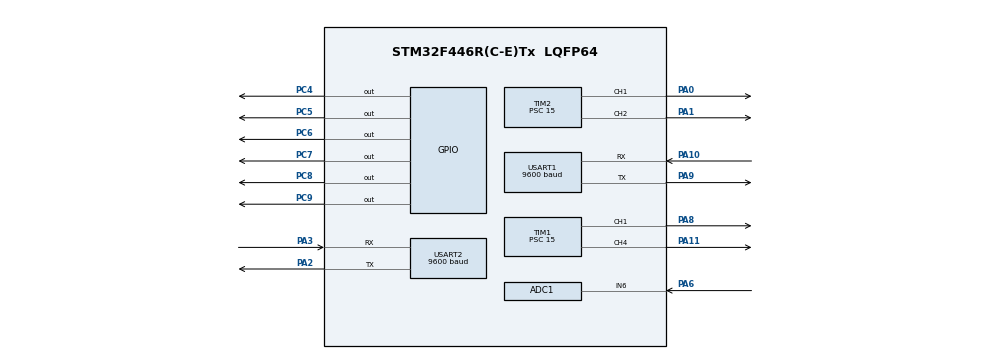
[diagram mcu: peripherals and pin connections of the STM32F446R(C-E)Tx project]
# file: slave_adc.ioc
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ADC1.Channel-0\#ChannelRegularConversion=ADC_CHANNEL_6
ADC1.NbrOfConversionFlag=1
ADC1.Rank-0\#ChannelRegularConversion=1
ADC1.Resolution=ADC_RESOLUTION_12B
ADC1.SamplingTime-0\#ChannelRegularConversion=ADC_SAMPLETIME_3CYCLES
ADC1.master=1
Mcu.Family=STM32F4
Mcu.Name=STM32F446R(C-E)Tx
Mcu.Package=LQFP64
NVIC.PriorityGroup=NVIC_PRIORITYGROUP_4
NVIC.USART1_IRQn=true\:0\:0\:false\:false\:true\:true\:true\:true
NVIC.USART2_IRQn=true\:0\:0\:false\:false\:true\:true\:true\:true
PA0-WKUP.Signal=S_TIM2_CH1_ETR
PA1.Signal=S_TIM2_CH2
PA10.Mode=Asynchronous
PA10.Signal=USART1_RX
PA11.Signal=S_TIM1_CH4
PA13.Mode=Serial_Wire
PA13.Signal=SYS_JTMS-SWDIO
PA14.Mode=Serial_Wire
PA14.Signal=SYS_JTCK-SWCLK
PA2.Mode=Asynchronous
PA2.Signal=USART2_TX
PA3.Mode=Asynchronous
PA3.Signal=USART2_RX
PA6.Signal=ADCx_IN6
PA8.Signal=S_TIM1_CH1
PA9.Mode=Asynchronous
PA9.Signal=USART1_TX
PC4.Signal=GPIO_Output
PC5.Signal=GPIO_Output
PC6.Signal=GPIO_Output
PC7.Signal=GPIO_Output
PC8.Signal=GPIO_Output
PC9.Signal=GPIO_Output
ProjectManager.HeapSize=0x200
ProjectManager.StackSize=0x400
ProjectManager.TargetToolchain=STM32CubeIDE
RCC.CortexFreq_Value=16000000
RCC.USBFreq_Value=96000000
RCC.VCOOutputFreq_Value=192000000
SH.ADCx_IN6.0=ADC1_IN6,IN6
SH.S_TIM1_CH1.0=TIM1_CH1,PWM Generation1 CH1
SH.S_TIM1_CH4.0=TIM1_CH4,PWM Generation4 CH4
SH.S_TIM2_CH1_ETR.0=TIM2_CH1,PWM Generation1 CH1
SH.S_TIM2_CH2.0=TIM2_CH2,PWM Generation2 CH2
TIM1.Channel-PWM\ Generation1\ CH1=TIM_CHANNEL_1
TIM1.Channel-PWM\ Generation4\ CH4=TIM_CHANNEL_4
TIM1.Period=19999
TIM1.Prescaler=15
TIM2.Channel-PWM\ Generation1\ CH1=TIM_CHANNEL_1
TIM2.Channel-PWM\ Generation2\ CH2=TIM_CHANNEL_2
TIM2.Period=999
TIM2.Prescaler=15
USART1.BaudRate=9600
USART1.VirtualMode=VM_ASYNC
USART2.BaudRate=9600
USART2.VirtualMode=VM_ASYNC
board=custom

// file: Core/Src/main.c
/* USER CODE BEGIN Header */
/**
  ******************************************************************************
  * @file           : main.c
  * @brief          : Main program body
  ******************************************************************************
  * @attention
  *
  * Copyright (c) 2023 STMicroelectronics.
  * All rights reserved.
  *
  * This software is licensed under terms that can be found in the LICENSE file
  * in the root directory of this software component.
  * If no LICENSE file comes with this software, it is provided AS-IS.
  *
  ******************************************************************************
  */
/* USER CODE END Header */
#include "main.h"
#include "adc.h"
#include "tim.h"
#include "usart.h"
#include "gpio.h"

/* USER CODE BEGIN PD */
#define BUFFER_LEN 2
/* USER CODE END PD */

/* USER CODE BEGIN PV */
uint8_t RX_BUFFER[BUFFER_LEN] = {125, 125};
uint8_t i = 0;
uint8_t n = BUFFER_LEN;
uint8_t temp = 0;
uint32_t voltage;
/* USER CODE END PV */

void SystemClock_Config(void);
/* USER CODE BEGIN PFP */
void HAL_UART_RxCpltCallback(UART_HandleTypeDef *huart)
{
	if(huart->Instance == huart1.Instance)
	{

      HAL_UART_Receive_IT(&huart1, RX_BUFFER, sizeof (RX_BUFFER));

	}
}
/* USER CODE END PFP */

int main(void)
{

  /* MCU Configuration--------------------------------------------------------*/

  /* Reset of all peripherals, Initializes the Flash interface and the Systick. */
  HAL_Init();

  /* Configure the system clock */
  SystemClock_Config();

  /* Initialize all configured peripherals */
  MX_GPIO_Init();
  MX_USART1_UART_Init();
  MX_USART2_UART_Init();
  MX_TIM1_Init();
  MX_TIM2_Init();
  MX_ADC1_Init();

  /* Infinite loop */
  uint8_t a,b,vout;
  uint32_t rawValue;
  uint32_t then = 0, tick = 0;
  uint32_t servo, dc;
  char msg[80];
  char msg1[80];
	  HAL_GPIO_WritePin(GPIOC, GPIO_PIN_4, GPIO_PIN_RESET);
	  HAL_GPIO_WritePin(GPIOC, GPIO_PIN_5, GPIO_PIN_RESET);
	  HAL_GPIO_WritePin(GPIOC, GPIO_PIN_6, GPIO_PIN_RESET);
	  HAL_GPIO_WritePin(GPIOC, GPIO_PIN_7, GPIO_PIN_RESET);
	  HAL_GPIO_WritePin(GPIOC, GPIO_PIN_8, GPIO_PIN_RESET);
	  HAL_GPIO_WritePin(GPIOC, GPIO_PIN_9, GPIO_PIN_RESET);

  while (1)
  {
	  tick = HAL_GetTick();
	  HAL_UART_Receive_IT(&huart1, RX_BUFFER, BUFFER_LEN);
	  	  sprintf(msg, "%d %d\r\n\n", RX_BUFFER[0],RX_BUFFER[1]);
	   	 HAL_UART_Transmit(&huart2, (uint8_t*) msg, strlen(msg), HAL_MAX_DELAY);

	 	 a = RX_BUFFER[0];
	 	 b=  RX_BUFFER[1];

//servo

	 	 servo = a*3.9 + 1000;
	 	 HAL_TIM_PWM_Start(&htim1, TIM_CHANNEL_4);
	 	__HAL_TIM_SET_COMPARE(&htim1, TIM_CHANNEL_4, servo);

	 	if (a<120) //lijevo
	 	{
	 		HAL_GPIO_WritePin(GPIOC, GPIO_PIN_4, GPIO_PIN_RESET);
	  	  HAL_GPIO_WritePin(GPIOC, GPIO_PIN_5, GPIO_PIN_RESET);
	  	  HAL_GPIO_WritePin(GPIOC, GPIO_PIN_6, GPIO_PIN_RESET);
	  	  HAL_GPIO_WritePin(GPIOC, GPIO_PIN_7, GPIO_PIN_RESET);
	  	  HAL_GPIO_WritePin(GPIOC, GPIO_PIN_8, GPIO_PIN_RESET);
	  	  HAL_GPIO_WritePin(GPIOC, GPIO_PIN_9, GPIO_PIN_RESET);
	  	  	if (tick - then >= 500)
			{
		        HAL_GPIO_TogglePin(GPIOC, GPIO_PIN_4);
		        HAL_GPIO_TogglePin(GPIOC, GPIO_PIN_6);
		        then = tick; // Reset then = now
			}

	 	}
	 	else if (a > 145) //desno
	 	{
		  	  HAL_GPIO_WritePin(GPIOC, GPIO_PIN_4, GPIO_PIN_RESET);
		  	  HAL_GPIO_WritePin(GPIOC, GPIO_PIN_5, GPIO_PIN_RESET);
		  	  HAL_GPIO_WritePin(GPIOC, GPIO_PIN_6, GPIO_PIN_RESET);
		  	  HAL_GPIO_WritePin(GPIOC, GPIO_PIN_7, GPIO_PIN_RESET);
		  	  HAL_GPIO_WritePin(GPIOC, GPIO_PIN_8, GPIO_PIN_RESET);
		  	  HAL_GPIO_WritePin(GPIOC, GPIO_PIN_9, GPIO_PIN_RESET);
		  	if (tick - then >= 500)
			{
				HAL_GPIO_TogglePin(GPIOC, GPIO_PIN_5);
				HAL_GPIO_TogglePin(GPIOC, GPIO_PIN_9);
				then = tick; // Reset then = now
			}
	 	}
	 	else
	 	{
		  	  HAL_GPIO_WritePin(GPIOC, GPIO_PIN_4, GPIO_PIN_RESET);
		  	  HAL_GPIO_WritePin(GPIOC, GPIO_PIN_5, GPIO_PIN_RESET);
		  	  HAL_GPIO_WritePin(GPIOC, GPIO_PIN_6, GPIO_PIN_RESET);
		  	  HAL_GPIO_WritePin(GPIOC, GPIO_PIN_7, GPIO_PIN_RESET);
		  	  HAL_GPIO_WritePin(GPIOC, GPIO_PIN_8, GPIO_PIN_RESET);
		  	  HAL_GPIO_WritePin(GPIOC, GPIO_PIN_9, GPIO_PIN_RESET);
	 	}

//dc
	 	if(b<120) //naprijed
	 	{
	 	HAL_TIM_PWM_Stop(&htim2, TIM_CHANNEL_1);
	 	dc = b*(-8.1)+1000;
	 	__HAL_TIM_SET_COMPARE(&htim2, TIM_CHANNEL_2, dc);
	 	HAL_TIM_PWM_Start(&htim2, TIM_CHANNEL_2);

	 	}

	 	else if(b>145) //nazad
	 	{
	 	HAL_TIM_PWM_Stop(&htim2, TIM_CHANNEL_2);
	 	dc = b*7.74-974.77;
	 	__HAL_TIM_SET_COMPARE(&htim2, TIM_CHANNEL_1, dc);
	 	HAL_TIM_PWM_Start(&htim2, TIM_CHANNEL_1);

	  	  HAL_GPIO_WritePin(GPIOC, GPIO_PIN_4, GPIO_PIN_RESET);
	  	  HAL_GPIO_WritePin(GPIOC, GPIO_PIN_5, GPIO_PIN_RESET);
	  	  HAL_GPIO_WritePin(GPIOC, GPIO_PIN_6, GPIO_PIN_RESET);
	  	  HAL_GPIO_WritePin(GPIOC, GPIO_PIN_7, GPIO_PIN_RESET);
	  	  HAL_GPIO_WritePin(GPIOC, GPIO_PIN_8, GPIO_PIN_RESET);
	  	  HAL_GPIO_WritePin(GPIOC, GPIO_PIN_9, GPIO_PIN_RESET);

			//sva 4 pokazivaca smjera
	  	  	if (tick - then >= 500)
			{
				HAL_GPIO_TogglePin(GPIOC, GPIO_PIN_4);
				HAL_GPIO_TogglePin(GPIOC, GPIO_PIN_5);
				HAL_GPIO_TogglePin(GPIOC, GPIO_PIN_6);
				HAL_GPIO_TogglePin(GPIOC, GPIO_PIN_9);

				then = tick; // Reset then = now
			}

	 	}

	 	else
	 	{
	 	HAL_TIM_PWM_Stop(&htim2, TIM_CHANNEL_1);
	 	  HAL_TIM_PWM_Stop(&htim2, TIM_CHANNEL_2);

	  	  HAL_GPIO_WritePin(GPIOC, GPIO_PIN_4, GPIO_PIN_RESET);
	  	  HAL_GPIO_WritePin(GPIOC, GPIO_PIN_5, GPIO_PIN_RESET);
	  	  HAL_GPIO_WritePin(GPIOC, GPIO_PIN_6, GPIO_PIN_RESET);
	  	  HAL_GPIO_WritePin(GPIOC, GPIO_PIN_7, GPIO_PIN_RESET);
	  	  HAL_GPIO_WritePin(GPIOC, GPIO_PIN_8, GPIO_PIN_RESET);
	  	  HAL_GPIO_WritePin(GPIOC, GPIO_PIN_9, GPIO_PIN_RESET);
	 	}

//svijetla
	 	  HAL_ADC_Start(&hadc1);
	 	  HAL_ADC_PollForConversion(&hadc1, HAL_MAX_DELAY);
	 	  rawValue = HAL_ADC_GetValue(&hadc1);
	 	  voltage = (3.3 / 4096) * rawValue;

	 	  sprintf(msg1, "voltage: %d\r\n\n", voltage);
	 	  HAL_UART_Transmit(&huart2, (uint32_t*) msg1, strlen(msg1), HAL_MAX_DELAY);
	 	  if (voltage < 2)
	 	  {
	 		HAL_GPIO_WritePin(GPIOC, GPIO_PIN_7, GPIO_PIN_SET);
	 		HAL_GPIO_WritePin(GPIOC, GPIO_PIN_8, GPIO_PIN_SET);
	 	  }
	 	  else
	 	  {
	 		HAL_GPIO_WritePin(GPIOC, GPIO_PIN_7, GPIO_PIN_RESET);
	 		HAL_GPIO_WritePin(GPIOC, GPIO_PIN_8, GPIO_PIN_RESET);
	 	  }

  }
  /* USER CODE END 3 */
}

void SystemClock_Config(void)
{
  RCC_OscInitTypeDef RCC_OscInitStruct = {0};
  RCC_ClkInitTypeDef RCC_ClkInitStruct = {0};

  /** Configure the main internal regulator output voltage
  */
  __HAL_RCC_PWR_CLK_ENABLE();
  __HAL_PWR_VOLTAGESCALING_CONFIG(PWR_REGULATOR_VOLTAGE_SCALE3);

  /** Initializes the RCC Oscillators according to the specified parameters
  * in the RCC_OscInitTypeDef structure.
  */
  RCC_OscInitStruct.OscillatorType = RCC_OSCILLATORTYPE_HSI;
  RCC_OscInitStruct.HSIState = RCC_HSI_ON;
  RCC_OscInitStruct.HSICalibrationValue = RCC_HSICALIBRATION_DEFAULT;
  RCC_OscInitStruct.PLL.PLLState = RCC_PLL_NONE;
  if (HAL_RCC_OscConfig(&RCC_OscInitStruct) != HAL_OK)
  {
    Error_Handler();
  }

  /** Initializes the CPU, AHB and APB buses clocks
  */
  RCC_ClkInitStruct.ClockType = RCC_CLOCKTYPE_HCLK|RCC_CLOCKTYPE_SYSCLK
                              |RCC_CLOCKTYPE_PCLK1|RCC_CLOCKTYPE_PCLK2;
  RCC_ClkInitStruct.SYSCLKSource = RCC_SYSCLKSOURCE_HSI;
  RCC_ClkInitStruct.AHBCLKDivider = RCC_SYSCLK_DIV1;
  RCC_ClkInitStruct.APB1CLKDivider = RCC_HCLK_DIV1;
  RCC_ClkInitStruct.APB2CLKDivider = RCC_HCLK_DIV1;

  if (HAL_RCC_ClockConfig(&RCC_ClkInitStruct, FLASH_LATENCY_0) != HAL_OK)
  {
    Error_Handler();
  }
}

void Error_Handler(void)
{
  __disable_irq();
  while (1)
  {
  }
}
